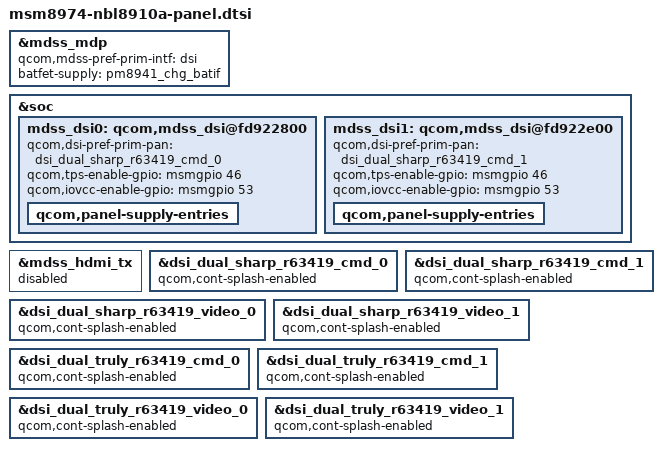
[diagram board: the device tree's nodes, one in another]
/* Copyright (c) 2018, The Linux Foundation. All rights reserved.
 *
 * This program is free software; you can redistribute it and/or modify
 * it under the terms of the GNU General Public License version 2 and
 * only version 2 as published by the Free Software Foundation.
 *
 * This program is distributed in the hope that it will be useful,
 * but WITHOUT ANY WARRANTY; without even the implied warranty of
 * MERCHANTABILITY or FITNESS FOR A PARTICULAR PURPOSE.  See the
 * GNU General Public License for more details.
 */

/include/ "panels/dsi-panel-sharp-r63419-dualmipi0-cmd.dtsi"
/include/ "panels/dsi-panel-sharp-r63419-dualmipi1-cmd.dtsi"
/include/ "panels/dsi-panel-sharp-r63419-dualmipi0-video.dtsi"
/include/ "panels/dsi-panel-sharp-r63419-dualmipi1-video.dtsi"

/include/ "panels/dsi-panel-truly-r63419-dualmipi0-cmd.dtsi"
/include/ "panels/dsi-panel-truly-r63419-dualmipi1-cmd.dtsi"
/include/ "panels/dsi-panel-truly-r63419-dualmipi0-video.dtsi"
/include/ "panels/dsi-panel-truly-r63419-dualmipi1-video.dtsi"

&mdss_mdp {
/delete-node/ qcom,mdss_dsi_orise_720p_video;
/delete-node/ qcom,mdss_dsi_toshiba_720p_video;
/delete-node/ qcom,mdss_dsi_sharp_qhd_video;
/delete-node/ qcom,mdss_dsi_generic_720p_cmd;
/delete-node/ qcom,mdss_dsi_jdi_1080p_video;
/delete-node/ qcom,dsi_jdi_qhd_video_0;
/delete-node/ qcom,dsi_jdi_qhd_video_1;
/delete-node/ qcom,mdss_dsi_jdi_qhd_dualmipi0_cmd;
/delete-node/ qcom,mdss_dsi_jdi_qhd_dualmipi1_cmd;
};

&soc {
	mdss_dsi0: qcom,mdss_dsi@fd922800 {
		qcom,dsi-pref-prim-pan = <&dsi_dual_sharp_r63419_cmd_0>;
		status = "ok";
		qcom,tps-enable-gpio = <&msmgpio 46 0>;
		qcom,iovcc-enable-gpio = <&msmgpio 53 0>;
		/delete-property/ vdd-supply;
		qcom,panel-supply-entries {
			/delete-node/ qcom,panel-supply-entry@0;
		};
	};

	mdss_dsi1: qcom,mdss_dsi@fd922e00 {
		qcom,dsi-pref-prim-pan = <&dsi_dual_sharp_r63419_cmd_1>;
		status = "ok";
		qcom,tps-enable-gpio = <&msmgpio 46 0>;
		qcom,iovcc-enable-gpio = <&msmgpio 53 0>;
		/delete-property/ vdd-supply;
		qcom,panel-supply-entries {
			/delete-node/ qcom,panel-supply-entry@0;
		};
	};
};

&mdss_hdmi_tx {
	status = "disabled";
};

&mdss_mdp {
	qcom,mdss-pref-prim-intf = "dsi";
	batfet-supply = <&pm8941_chg_batif>;
};

&dsi_dual_sharp_r63419_cmd_0 {
	qcom,cont-splash-enabled;
};
&dsi_dual_sharp_r63419_cmd_1 {
	qcom,cont-splash-enabled;
};
&dsi_dual_sharp_r63419_video_0 {
	qcom,cont-splash-enabled;
};
&dsi_dual_sharp_r63419_video_1 {
	qcom,cont-splash-enabled;
};

&dsi_dual_truly_r63419_cmd_0 {
	qcom,cont-splash-enabled;
};
&dsi_dual_truly_r63419_cmd_1 {
	qcom,cont-splash-enabled;
};
&dsi_dual_truly_r63419_video_0 {
	qcom,cont-splash-enabled;
};
&dsi_dual_truly_r63419_video_1 {
	qcom,cont-splash-enabled;
};
